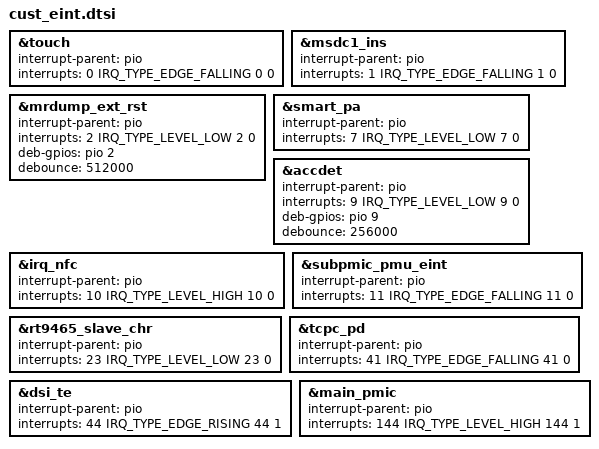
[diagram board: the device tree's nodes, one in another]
/*
 * Generated by MTK SP DrvGen Version: 3.5.160809 for MT6765.
 * 2026-08-02 08:23:30
 * Do Not Modify The File.
 * Copyright Mediatek Inc. (c) 2016.
*/

/*************************
 * EINT DTSI File
*************************/

#include <dt-bindings/interrupt-controller/irq.h>
#include <dt-bindings/interrupt-controller/arm-gic.h>

&touch {
	interrupt-parent = <&pio>;
	interrupts = <0 IRQ_TYPE_EDGE_FALLING 0 0>;
	status = "okay";
};

&msdc1_ins {
	interrupt-parent = <&pio>;
	interrupts = <1 IRQ_TYPE_EDGE_FALLING 1 0>;
	status = "okay";
};

&mrdump_ext_rst {
	interrupt-parent = <&pio>;
	interrupts = <2 IRQ_TYPE_LEVEL_LOW 2 0>;
	deb-gpios = <&pio 2 0>;
	debounce = <512000>;
	status = "okay";
};

&smart_pa {
	interrupt-parent = <&pio>;
	interrupts = <7 IRQ_TYPE_LEVEL_LOW 7 0>;
	status = "okay";
};

&accdet {
	interrupt-parent = <&pio>;
	interrupts = <9 IRQ_TYPE_LEVEL_LOW 9 0>;
	deb-gpios = <&pio 9 0>;
	debounce = <256000>;
	status = "okay";
};

&irq_nfc {
	interrupt-parent = <&pio>;
	interrupts = <10 IRQ_TYPE_LEVEL_HIGH 10 0>;
	status = "okay";
};

&subpmic_pmu_eint {
	interrupt-parent = <&pio>;
	interrupts = <11 IRQ_TYPE_EDGE_FALLING 11 0>;
	status = "okay";
};

&rt9465_slave_chr {
	interrupt-parent = <&pio>;
	interrupts = <23 IRQ_TYPE_LEVEL_LOW 23 0>;
	status = "okay";
};

&tcpc_pd {
	interrupt-parent = <&pio>;
	interrupts = <41 IRQ_TYPE_EDGE_FALLING 41 0>;
	status = "okay";
};

&dsi_te {
	interrupt-parent = <&pio>;
	interrupts = <44 IRQ_TYPE_EDGE_RISING 44 1>;
	status = "okay";
};

&main_pmic {
	interrupt-parent = <&pio>;
	interrupts = <144 IRQ_TYPE_LEVEL_HIGH 144 1>;
	status = "okay";
};

